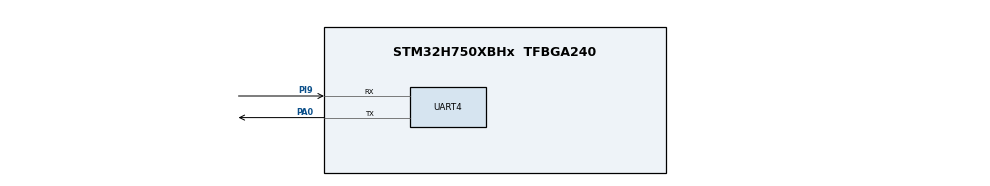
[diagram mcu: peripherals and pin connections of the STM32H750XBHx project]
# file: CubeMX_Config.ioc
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3rdParty.I-CUBE-CoreMark.0.1.0.ApplicationCcDeviceJjApplication=CoreMarkApp
3rdParty.I-CUBE-CoreMark.0.1.0.ITERATIONS=1000
3rdParty.I-CUBE-CoreMark.0.1.0.PRINTF_UART_PORT=huart4
3rdParty.I-CUBE-CoreMark.0.1.0.UtilityJjMISC=true
CORTEX_M7.CPU_DCache=Enabled
CORTEX_M7.CPU_ICache=Enabled
Mcu.Family=STM32H7
Mcu.Name=STM32H750XBHx
Mcu.Package=TFBGA240
NVIC.PriorityGroup=NVIC_PRIORITYGROUP_4
PA0.Mode=Asynchronous
PA0.Signal=UART4_TX
PA4.Signal=SPI1_NSS
PA5.Signal=SPI1_SCK
PF7.GPIO_Speed=GPIO_SPEED_FREQ_VERY_HIGH
PF7.Signal=QUADSPI_BK1_IO2
PF8.GPIO_Speed=GPIO_SPEED_FREQ_VERY_HIGH
PF8.Signal=QUADSPI_BK1_IO0
PF9.GPIO_Speed=GPIO_SPEED_FREQ_VERY_HIGH
PF9.Signal=QUADSPI_BK1_IO1
PG11.GPIO_Speed=GPIO_SPEED_FREQ_VERY_HIGH
PG11.Signal=ETH_TX_EN
PG14.GPIO_Speed=GPIO_SPEED_FREQ_VERY_HIGH
PG14.Signal=ETH_TXD1
PG6.GPIO_Speed=GPIO_SPEED_FREQ_VERY_HIGH
PG6.Signal=QUADSPI_BK1_NCS
PH0-OSC_IN\ (PH0).Mode=HSE-External-Oscillator
PH0-OSC_IN\ (PH0).Signal=RCC_OSC_IN
PH1-OSC_OUT\ (PH1).Mode=HSE-External-Oscillator
PH1-OSC_OUT\ (PH1).Signal=RCC_OSC_OUT
PH5.GPIO_Speed_High_Default=GPIO_SPEED_FREQ_VERY_HIGH
PH5.Signal=FMC_SDNWE
PI12.GPIO_Speed=GPIO_SPEED_FREQ_VERY_HIGH
PI12.Signal=LTDC_HSYNC
PI13.GPIO_Speed=GPIO_SPEED_FREQ_VERY_HIGH
PI13.Signal=LTDC_VSYNC
PI14.GPIO_Speed=GPIO_SPEED_FREQ_VERY_HIGH
PI14.Signal=LTDC_CLK
PI15.GPIO_Speed=GPIO_SPEED_FREQ_VERY_HIGH
PI15.Signal=LTDC_R0
PI9.Mode=Asynchronous
PI9.Signal=UART4_RX
PJ10.GPIO_Speed=GPIO_SPEED_FREQ_VERY_HIGH
PJ10.Signal=LTDC_G3
PJ11.GPIO_Speed=GPIO_SPEED_FREQ_VERY_HIGH
PJ11.Signal=LTDC_G4
PJ12.GPIO_Speed=GPIO_SPEED_FREQ_VERY_HIGH
PJ12.Signal=LTDC_B0
PJ13.GPIO_Speed=GPIO_SPEED_FREQ_VERY_HIGH
PJ13.Signal=LTDC_B1
PJ2.GPIO_Speed=GPIO_SPEED_FREQ_VERY_HIGH
PJ2.Signal=LTDC_R3
PJ3.GPIO_Speed=GPIO_SPEED_FREQ_VERY_HIGH
PJ3.Signal=LTDC_R4
PJ4.GPIO_Speed=GPIO_SPEED_FREQ_VERY_HIGH
PJ4.Signal=LTDC_R5
PJ5.GPIO_Speed=GPIO_SPEED_FREQ_VERY_HIGH
PJ5.Signal=LTDC_R6
PJ6.GPIO_Speed=GPIO_SPEED_FREQ_VERY_HIGH
PJ6.Signal=LTDC_R7
PJ9.GPIO_Speed=GPIO_SPEED_FREQ_VERY_HIGH
PJ9.Signal=LTDC_G2
PK0.GPIO_Speed=GPIO_SPEED_FREQ_VERY_HIGH
PK0.Signal=LTDC_G5
PK1.GPIO_Speed=GPIO_SPEED_FREQ_VERY_HIGH
PK1.Signal=LTDC_G6
PK2.GPIO_Speed=GPIO_SPEED_FREQ_VERY_HIGH
PK2.Signal=LTDC_G7
PK3.GPIO_Speed=GPIO_SPEED_FREQ_VERY_HIGH
PK3.Signal=LTDC_B4
PK4.GPIO_Speed=GPIO_SPEED_FREQ_VERY_HIGH
PK4.Signal=LTDC_B5
PK5.GPIO_Speed=GPIO_SPEED_FREQ_VERY_HIGH
PK5.Signal=LTDC_B6
PK6.GPIO_Speed=GPIO_SPEED_FREQ_VERY_HIGH
PK6.Signal=LTDC_B7
ProjectManager.HeapSize=0x200
ProjectManager.StackSize=0x4000
ProjectManager.TargetToolchain=EWARM V8.50
RCC.ADCFreq_Value=200000000
RCC.APB1Freq_Value=120000000
RCC.APB2Freq_Value=120000000
RCC.APB3Freq_Value=120000000
RCC.APB4Freq_Value=120000000
RCC.CortexFreq_Value=480000000
RCC.D1PPRE=RCC_APB3_DIV2
RCC.D2PPRE1=RCC_APB1_DIV2
RCC.D2PPRE2=RCC_APB2_DIV2
RCC.D3PPRE=RCC_APB4_DIV2
RCC.DIVM1=5
RCC.DIVM2=2
RCC.DIVM3=5
RCC.DIVN1=192
RCC.DIVN2=64
RCC.DIVN3=160
RCC.DIVP2=4
RCC.DIVP3=8
RCC.DIVQ3=8
RCC.DIVR2=4
RCC.DIVR3=24
RCC.FMCCLockSelection=RCC_FMCCLKSOURCE_PLL2
RCC.HCLKFreq_Value=240000000
RCC.HPRE=RCC_HCLK_DIV2
RCC.PLL2FRACN=0
RCC.PLLFRACN=0
RCC.PLLSourceVirtual=RCC_PLLSOURCE_HSE
RCC.SDMMC1CLockSelection=RCC_SDMMCCLKSOURCE_PLL2
RCC.SPI123CLockSelection=RCC_SPI123CLKSOURCE_PLL2
RCC.SYSCLKFreq_VALUE=480000000
RCC.SYSCLKSource=RCC_SYSCLKSOURCE_PLLCLK
RCC.Spi45ClockSelection=RCC_SPI45CLKSOURCE_PLL3
RCC.USBCLockSelection=RCC_USBCLKSOURCE_HSI48
RCC.USBFreq_Value=48000000
SH.FMC_SDNWE.0=FMC_SDNWE
VP_3rdParty.I-CUBE-CoreMark_VS_DeviceJjApplication_0.1.0_0.1.0.Mode=DeviceJjApplication
VP_3rdParty.I-CUBE-CoreMark_VS_UtilityJjMISC_0.1.0_0.1.0.Mode=UtilityJjMISC
VP_MEMORYMAP_VS_MEMORYMAP.Mode=CurAppReg
board=custom

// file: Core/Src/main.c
/* USER CODE BEGIN Header */
/**
  ******************************************************************************
  * @file           : main.c
  * @brief          : Main program body
  ******************************************************************************
  * @attention
  *
  * Copyright (c) 2025 STMicroelectronics.
  * All rights reserved.
  *
  * This software is licensed under terms that can be found in the LICENSE file
  * in the root directory of this software component.
  * If no LICENSE file comes with this software, it is provided AS-IS.
  *
  ******************************************************************************
  */
/* USER CODE END Header */
#include "main.h"
#include "app_coremarkapp.h"

UART_HandleTypeDef huart4;

void SystemClock_Config(void);
static void MX_GPIO_Init(void);
static void MX_UART4_Init(void);

/* USER CODE BEGIN 0 */
#include <yfuns.h>
// #include "stm32h7xx_hal.h"

// extern UART_HandleTypeDef huart4;

size_t __write(int handle, const unsigned char *buffer, size_t size)
{
    if (buffer == NULL) {
        return 0;
    }

    // ??? stdout ? stderr
    if (handle != _LLIO_STDOUT && handle != _LLIO_STDERR) {
        return _LLIO_ERROR;
    }

    // ?? UART4 ????
    HAL_UART_Transmit(&huart4, (uint8_t *)buffer, size, HAL_MAX_DELAY);

    return size;
}
/* USER CODE END 0 */

int main(void)
{

  /* Enable the CPU Cache */

  /* Enable I-Cache---------------------------------------------------------*/
  SCB_EnableICache();

  /* Enable D-Cache---------------------------------------------------------*/
  SCB_EnableDCache();

  /* MCU Configuration--------------------------------------------------------*/

  /* Reset of all peripherals, Initializes the Flash interface and the Systick. */
  HAL_Init();

  /* Configure the system clock */
  SystemClock_Config();

  /* Initialize all configured peripherals */
  MX_GPIO_Init();
  MX_UART4_Init();
  MX_CoreMarkApp_Init();

  /* Infinite loop */
  while (1)
  {

  MX_CoreMarkApp_Process();
  }
}

void SystemClock_Config(void)
{
  RCC_OscInitTypeDef RCC_OscInitStruct = {0};
  RCC_ClkInitTypeDef RCC_ClkInitStruct = {0};

  /** Supply configuration update enable
  */
  HAL_PWREx_ConfigSupply(PWR_LDO_SUPPLY);

  /** Configure the main internal regulator output voltage
  */
  __HAL_PWR_VOLTAGESCALING_CONFIG(PWR_REGULATOR_VOLTAGE_SCALE1);

  while(!__HAL_PWR_GET_FLAG(PWR_FLAG_VOSRDY)) {}

  __HAL_RCC_SYSCFG_CLK_ENABLE();
  __HAL_PWR_VOLTAGESCALING_CONFIG(PWR_REGULATOR_VOLTAGE_SCALE0);

  while(!__HAL_PWR_GET_FLAG(PWR_FLAG_VOSRDY)) {}

  /** Initializes the RCC Oscillators according to the specified parameters
  * in the RCC_OscInitTypeDef structure.
  */
  RCC_OscInitStruct.OscillatorType = RCC_OSCILLATORTYPE_HSE;
  RCC_OscInitStruct.HSEState = RCC_HSE_ON;
  RCC_OscInitStruct.PLL.PLLState = RCC_PLL_ON;
  RCC_OscInitStruct.PLL.PLLSource = RCC_PLLSOURCE_HSE;
  RCC_OscInitStruct.PLL.PLLM = 5;
  RCC_OscInitStruct.PLL.PLLN = 192;
  RCC_OscInitStruct.PLL.PLLP = 2;
  RCC_OscInitStruct.PLL.PLLQ = 2;
  RCC_OscInitStruct.PLL.PLLR = 2;
  RCC_OscInitStruct.PLL.PLLRGE = RCC_PLL1VCIRANGE_2;
  RCC_OscInitStruct.PLL.PLLVCOSEL = RCC_PLL1VCOWIDE;
  RCC_OscInitStruct.PLL.PLLFRACN = 0;
  if (HAL_RCC_OscConfig(&RCC_OscInitStruct) != HAL_OK)
  {
    Error_Handler();
  }

  /** Initializes the CPU, AHB and APB buses clocks
  */
  RCC_ClkInitStruct.ClockType = RCC_CLOCKTYPE_HCLK|RCC_CLOCKTYPE_SYSCLK
                              |RCC_CLOCKTYPE_PCLK1|RCC_CLOCKTYPE_PCLK2
                              |RCC_CLOCKTYPE_D3PCLK1|RCC_CLOCKTYPE_D1PCLK1;
  RCC_ClkInitStruct.SYSCLKSource = RCC_SYSCLKSOURCE_PLLCLK;
  RCC_ClkInitStruct.SYSCLKDivider = RCC_SYSCLK_DIV1;
  RCC_ClkInitStruct.AHBCLKDivider = RCC_HCLK_DIV2;
  RCC_ClkInitStruct.APB3CLKDivider = RCC_APB3_DIV2;
  RCC_ClkInitStruct.APB1CLKDivider = RCC_APB1_DIV2;
  RCC_ClkInitStruct.APB2CLKDivider = RCC_APB2_DIV2;
  RCC_ClkInitStruct.APB4CLKDivider = RCC_APB4_DIV2;

  if (HAL_RCC_ClockConfig(&RCC_ClkInitStruct, FLASH_LATENCY_4) != HAL_OK)
  {
    Error_Handler();
  }
}

static void MX_UART4_Init(void)
{

  huart4.Instance = UART4;
  huart4.Init.BaudRate = 115200;
  huart4.Init.WordLength = UART_WORDLENGTH_8B;
  huart4.Init.StopBits = UART_STOPBITS_1;
  huart4.Init.Parity = UART_PARITY_NONE;
  huart4.Init.Mode = UART_MODE_TX_RX;
  huart4.Init.HwFlowCtl = UART_HWCONTROL_NONE;
  huart4.Init.OverSampling = UART_OVERSAMPLING_16;
  huart4.Init.OneBitSampling = UART_ONE_BIT_SAMPLE_DISABLE;
  huart4.Init.ClockPrescaler = UART_PRESCALER_DIV1;
  huart4.AdvancedInit.AdvFeatureInit = UART_ADVFEATURE_NO_INIT;
  if (HAL_UART_Init(&huart4) != HAL_OK)
  {
    Error_Handler();
  }
  if (HAL_UARTEx_SetTxFifoThreshold(&huart4, UART_TXFIFO_THRESHOLD_1_8) != HAL_OK)
  {
    Error_Handler();
  }
  if (HAL_UARTEx_SetRxFifoThreshold(&huart4, UART_RXFIFO_THRESHOLD_1_8) != HAL_OK)
  {
    Error_Handler();
  }
  if (HAL_UARTEx_DisableFifoMode(&huart4) != HAL_OK)
  {
    Error_Handler();
  }

}

static void MX_GPIO_Init(void)
{
  GPIO_InitTypeDef GPIO_InitStruct = {0};

  /* GPIO Ports Clock Enable */
  __HAL_RCC_GPIOK_CLK_ENABLE();
  __HAL_RCC_GPIOG_CLK_ENABLE();
  __HAL_RCC_GPIOJ_CLK_ENABLE();
  __HAL_RCC_GPIOI_CLK_ENABLE();
  __HAL_RCC_GPIOH_CLK_ENABLE();
  __HAL_RCC_GPIOF_CLK_ENABLE();
  __HAL_RCC_GPIOA_CLK_ENABLE();

  /*Configure GPIO pins : PK5 PK4 PK6 PK3
                           PK2 PK0 PK1 */
  GPIO_InitStruct.Pin = GPIO_PIN_5|GPIO_PIN_4|GPIO_PIN_6|GPIO_PIN_3
                          |GPIO_PIN_2|GPIO_PIN_0|GPIO_PIN_1;
  GPIO_InitStruct.Mode = GPIO_MODE_AF_PP;
  GPIO_InitStruct.Pull = GPIO_NOPULL;
  GPIO_InitStruct.Speed = GPIO_SPEED_FREQ_VERY_HIGH;
  GPIO_InitStruct.Alternate = GPIO_AF14_LTDC;
  HAL_GPIO_Init(GPIOK, &GPIO_InitStruct);

  /*Configure GPIO pins : PG11 PG14 */
  GPIO_InitStruct.Pin = GPIO_PIN_11|GPIO_PIN_14;
  GPIO_InitStruct.Mode = GPIO_MODE_AF_PP;
  GPIO_InitStruct.Pull = GPIO_NOPULL;
  GPIO_InitStruct.Speed = GPIO_SPEED_FREQ_VERY_HIGH;
  GPIO_InitStruct.Alternate = GPIO_AF11_ETH;
  HAL_GPIO_Init(GPIOG, &GPIO_InitStruct);

  /*Configure GPIO pins : PJ12 PJ13 PJ11 PJ10
                           PJ9 PJ6 PJ5 PJ2
                           PJ3 PJ4 */
  GPIO_InitStruct.Pin = GPIO_PIN_12|GPIO_PIN_13|GPIO_PIN_11|GPIO_PIN_10
                          |GPIO_PIN_9|GPIO_PIN_6|GPIO_PIN_5|GPIO_PIN_2
                          |GPIO_PIN_3|GPIO_PIN_4;
  GPIO_InitStruct.Mode = GPIO_MODE_AF_PP;
  GPIO_InitStruct.Pull = GPIO_NOPULL;
  GPIO_InitStruct.Speed = GPIO_SPEED_FREQ_VERY_HIGH;
  GPIO_InitStruct.Alternate = GPIO_AF14_LTDC;
  HAL_GPIO_Init(GPIOJ, &GPIO_InitStruct);

  /*Configure GPIO pin : PG6 */
  GPIO_InitStruct.Pin = GPIO_PIN_6;
  GPIO_InitStruct.Mode = GPIO_MODE_AF_PP;
  GPIO_InitStruct.Pull = GPIO_NOPULL;
  GPIO_InitStruct.Speed = GPIO_SPEED_FREQ_VERY_HIGH;
  GPIO_InitStruct.Alternate = GPIO_AF10_QUADSPI;
  HAL_GPIO_Init(GPIOG, &GPIO_InitStruct);

  /*Configure GPIO pins : PI12 PI13 PI14 PI15 */
  GPIO_InitStruct.Pin = GPIO_PIN_12|GPIO_PIN_13|GPIO_PIN_14|GPIO_PIN_15;
  GPIO_InitStruct.Mode = GPIO_MODE_AF_PP;
  GPIO_InitStruct.Pull = GPIO_NOPULL;
  GPIO_InitStruct.Speed = GPIO_SPEED_FREQ_VERY_HIGH;
  GPIO_InitStruct.Alternate = GPIO_AF14_LTDC;
  HAL_GPIO_Init(GPIOI, &GPIO_InitStruct);

  /*Configure GPIO pin : PF7 */
  GPIO_InitStruct.Pin = GPIO_PIN_7;
  GPIO_InitStruct.Mode = GPIO_MODE_AF_PP;
  GPIO_InitStruct.Pull = GPIO_NOPULL;
  GPIO_InitStruct.Speed = GPIO_SPEED_FREQ_VERY_HIGH;
  GPIO_InitStruct.Alternate = GPIO_AF9_QUADSPI;
  HAL_GPIO_Init(GPIOF, &GPIO_InitStruct);

  /*Configure GPIO pins : PF8 PF9 */
  GPIO_InitStruct.Pin = GPIO_PIN_8|GPIO_PIN_9;
  GPIO_InitStruct.Mode = GPIO_MODE_AF_PP;
  GPIO_InitStruct.Pull = GPIO_NOPULL;
  GPIO_InitStruct.Speed = GPIO_SPEED_FREQ_VERY_HIGH;
  GPIO_InitStruct.Alternate = GPIO_AF10_QUADSPI;
  HAL_GPIO_Init(GPIOF, &GPIO_InitStruct);

  /*Configure GPIO pin : PH5 */
  GPIO_InitStruct.Pin = GPIO_PIN_5;
  GPIO_InitStruct.Mode = GPIO_MODE_AF_PP;
  GPIO_InitStruct.Pull = GPIO_NOPULL;
  GPIO_InitStruct.Speed = GPIO_SPEED_FREQ_VERY_HIGH;
  GPIO_InitStruct.Alternate = GPIO_AF12_FMC;
  HAL_GPIO_Init(GPIOH, &GPIO_InitStruct);

  /*Configure GPIO pins : PA5 PA4 */
  GPIO_InitStruct.Pin = GPIO_PIN_5|GPIO_PIN_4;
  GPIO_InitStruct.Mode = GPIO_MODE_AF_PP;
  GPIO_InitStruct.Pull = GPIO_NOPULL;
  GPIO_InitStruct.Speed = GPIO_SPEED_FREQ_LOW;
  GPIO_InitStruct.Alternate = GPIO_AF5_SPI1;
  HAL_GPIO_Init(GPIOA, &GPIO_InitStruct);

}

void Error_Handler(void)
{
  __disable_irq();
  while (1)
  {
  }
}
